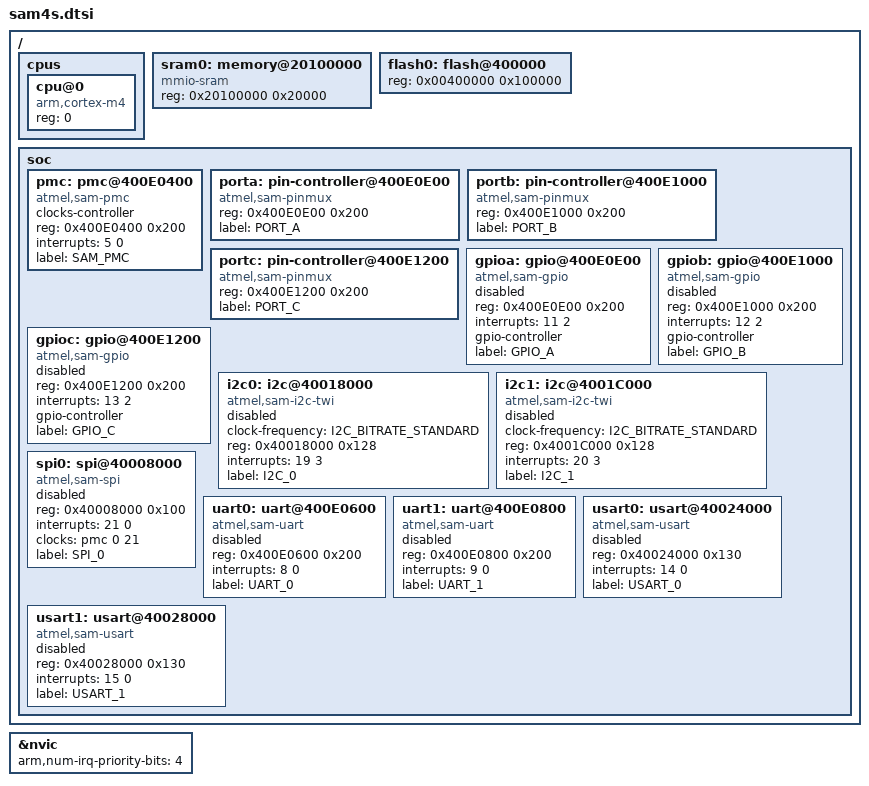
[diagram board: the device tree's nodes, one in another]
/*
 * Copyright (c) 2017 Justin Watson
 *
 * SPDX-License-Identifier: Apache-2.0
 */

#include <arm/armv7-m.dtsi>
#include <atmel/sam4s-pinctrl.dtsi>
#include <dt-bindings/i2c/i2c.h>

/ {
	cpus {
		#address-cells = <1>;
		#size-cells = <0>;

		cpu@0 {
			device_type = "cpu";
			compatible = "arm,cortex-m4";
			reg = <0>;
		};
	};

	sram0: memory@20100000 {
		device_type = "memory";
		compatible = "mmio-sram";
		reg = <0x20100000 0x20000>;
	};

	flash0: flash@400000 {
		reg = <0x00400000 0x100000>;
	};

	soc {
		pmc: pmc@400E0400 {
			compatible = "atmel,sam-pmc";
			clocks-controller;
			#clocks-cells = <2>;
			reg = <0x400E0400 0x200>;
			interrupts = <5 0>;
			label = "SAM_PMC";
		};

		porta: pin-controller@400E0E00 {
			compatible = "atmel,sam-pinmux";
			#address-cells = <1>;
			#size-cells = <1>;
			reg = <0x400E0E00 0x200>;
			label = "PORT_A";
		};
		
		portb: pin-controller@400E1000 {
			compatible = "atmel,sam-pinmux";
			#address-cells = <1>;
			#size-cells = <1>;
			reg = <0x400E1000 0x200>;
			label = "PORT_B";
		};
		
		portc: pin-controller@400E1200 {
			compatible = "atmel,sam-pinmux";
			#address-cells = <1>;
			#size-cells = <1>;
			reg = <0x400E1200 0x200>;
			label = "PORT_C";
		};
		
		gpioa: gpio@400E0E00 {
			compatible = "atmel,sam-gpio";
			reg = <0x400E0E00 0x200>;
			interrupts = <11 2>;
			gpio-controller;
			#gpio-cells = <2>;
			label = "GPIO_A";
			status = "disabled";
		};

		gpiob: gpio@400E1000 {
			compatible = "atmel,sam-gpio";
			reg = <0x400E1000 0x200>;
			interrupts = <12 2>;
			gpio-controller;
			#gpio-cells = <2>;
			label = "GPIO_B";
			status = "disabled";
		};

		gpioc: gpio@400E1200 {
			compatible = "atmel,sam-gpio";
			reg = <0x400E1200 0x200>;
			interrupts = <13 2>;
			gpio-controller;
			#gpio-cells = <2>;
			label = "GPIO_C";
			status = "disabled";
		};
		
		i2c0: i2c@40018000 {
			compatible = "atmel,sam-i2c-twi";
			clock-frequency = <I2C_BITRATE_STANDARD>;
			reg = <0x40018000 0x128>;
			interrupts = <19 3>;
			label = "I2C_0";
			status = "disabled";
		};

		i2c1: i2c@4001C000 {
			compatible = "atmel,sam-i2c-twi";
			clock-frequency = <I2C_BITRATE_STANDARD>;
			reg = <0x4001C000 0x128>;
			interrupts = <20 3>;
			label = "I2C_1";
			status = "disabled";
		};
		
		spi0: spi@40008000 {
			compatible = "atmel,sam-spi";
			reg = <0x40008000 0x100>;
			interrupts = <21 0>;
			clocks = <&pmc 0 21>;
			label = "SPI_0";
			status = "disabled";
		};
	
		uart0: uart@400E0600 {
			compatible = "atmel,sam-uart";
			reg = <0x400E0600 0x200>;
			interrupts = <8 0>;
			label = "UART_0";
			status = "disabled";
		};

		uart1: uart@400E0800 {
			compatible = "atmel,sam-uart";
			reg = <0x400E0800 0x200>;
			interrupts = <9 0>;
			label = "UART_1";
			status = "disabled";
		};

		usart0: usart@40024000 {
			compatible = "atmel,sam-usart";
			reg = <0x40024000 0x130>;
			interrupts = <14 0>;
			label = "USART_0";
			status = "disabled";
		};

		usart1: usart@40028000 {
			compatible = "atmel,sam-usart";
			reg = <0x40028000 0x130>;
			interrupts = <15 0>;
			label = "USART_1";
			status = "disabled";
		};
	};
};

&nvic {
	arm,num-irq-priority-bits = <4>;
};
